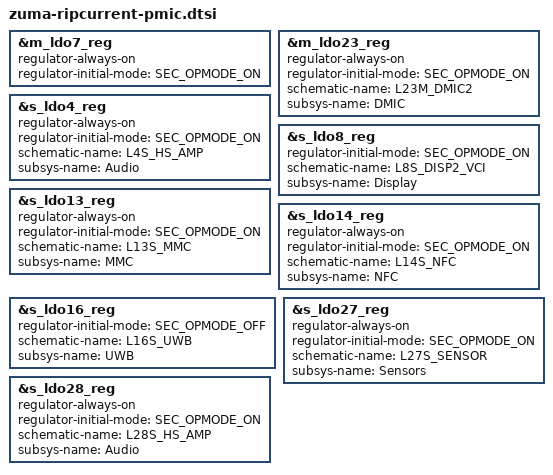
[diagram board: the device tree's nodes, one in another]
// SPDX-License-Identifier: GPL-2.0-only
/*
 * Ripcurrent PMIC settings
 *
 * Copyright 2023 Google LLC.
 *
 */

&m_ldo7_reg {
	regulator-always-on;
	regulator-initial-mode = <SEC_OPMODE_ON>;
};

&m_ldo23_reg {
	regulator-always-on;
	regulator-initial-mode = <SEC_OPMODE_ON>;
	schematic-name = "L23M_DMIC2";
	subsys-name = "DMIC";
};

&s_ldo4_reg {
	regulator-always-on;
	regulator-initial-mode = <SEC_OPMODE_ON>;
	schematic-name = "L4S_HS_AMP";
	subsys-name = "Audio";
};

&s_ldo8_reg {
	regulator-initial-mode = <SEC_OPMODE_ON>;
	schematic-name = "L8S_DISP2_VCI";
	subsys-name = "Display";
};

&s_ldo13_reg {
	regulator-always-on;
	regulator-initial-mode = <SEC_OPMODE_ON>;
	schematic-name = "L13S_MMC";
	subsys-name = "MMC";
};

&s_ldo14_reg {
	regulator-always-on;
	regulator-initial-mode = <SEC_OPMODE_ON>;
	schematic-name = "L14S_NFC";
	subsys-name = "NFC";
};

&s_ldo16_reg {
	regulator-initial-mode = <SEC_OPMODE_OFF>;
	schematic-name = "L16S_UWB";
	subsys-name = "UWB";
};

&s_ldo27_reg {
	regulator-always-on;
	regulator-initial-mode = <SEC_OPMODE_ON>;
	schematic-name = "L27S_SENSOR";
	subsys-name = "Sensors";
};

&s_ldo28_reg {
	regulator-always-on;
	regulator-initial-mode = <SEC_OPMODE_ON>;
	schematic-name = "L28S_HS_AMP";
	subsys-name = "Audio";
};
